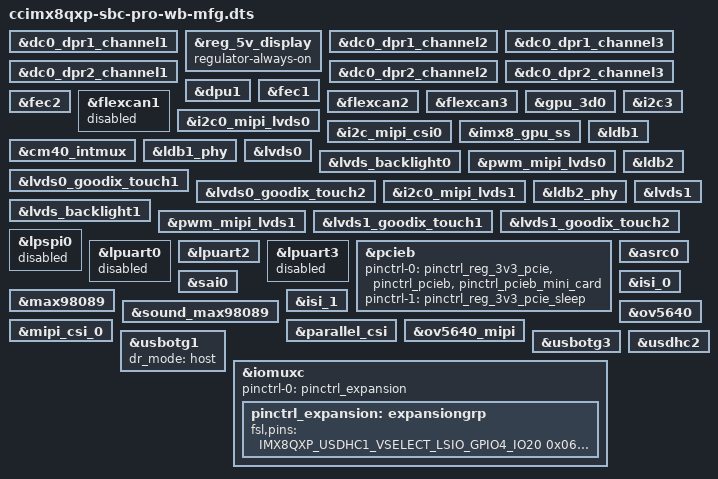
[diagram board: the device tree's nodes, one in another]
/*
 * Copyright 2018, Digi International Inc.
 *
 * Permission to use, copy, modify, and/or distribute this software for any
 * purpose with or without fee is hereby granted, provided that the above
 * copyright notice and this permission notice appear in all copies.
 * THE SOFTWARE IS PROVIDED "AS IS" AND THE AUTHOR DISCLAIMS ALL WARRANTIES
 * WITH REGARD TO THIS SOFTWARE INCLUDING ALL IMPLIED WARRANTIES OF
 * MERCHANTABILITY AND FITNESS. IN NO EVENT SHALL THE AUTHOR BE LIABLE FOR
 * ANY SPECIAL, DIRECT, INDIRECT, OR CONSEQUENTIAL DAMAGES OR ANY DAMAGES
 * WHATSOEVER RESULTING FROM LOSS OF USE, DATA OR PROFITS, WHETHER IN AN
 * ACTION OF CONTRACT, NEGLIGENCE OR OTHER TORTIOUS ACTION, ARISING OUT OF
 * OR IN CONNECTION WITH THE USE OR PERFORMANCE OF THIS SOFTWARE.
 */

/dts-v1/;

/* i.MX8QXP CPU */
#include "../freescale/imx8qxp.dtsi"
/* Digi ConnectCore 8X (WiFi/bluetooth variant) */
#include "ccimx8x-wb.dtsi"
/* Digi ConnectCore 8X SBC Pro */
#include "ccimx8x-sbc-pro.dtsi"

&dc0_dpr1_channel1 {
	status = "okay";
};

&reg_5v_display {
	regulator-always-on;
};

&dc0_dpr1_channel2 {
	status = "okay";
};

&dc0_dpr1_channel3 {
	status = "okay";
};

&dc0_dpr2_channel1 {
	status = "okay";
};

&dc0_dpr2_channel2 {
	status = "okay";
};

&dc0_dpr2_channel3 {
	status = "okay";
};

&dpu1 {
	status = "okay";
};

&fec1 {
	status = "okay";
};

&fec2 {
	status = "okay";
};

/*
 * CAN0
 * Conflicts with LPUART0 RTS/CTS lines.
 * Before enabling the port you need to configure
 * lpuart0 node as 2 wires.
 */
&flexcan1 {
	status = "disabled";
};

/* CAN1 on expansion header */
&flexcan2 {
	status = "okay";
};

/*
 * CAN2 on expansion header.
 * Conflicts with LPUART3 RX/TX lines.
 */
&flexcan3 {
	status = "okay";
};

&gpu_3d0 {
	status = "okay";
};

/*
 * I2C3 connected to Audio codec and USB 3.0 PD PHY.
 * Also available on:
 * - Expansion header
 * - PCIe connector
 * - Parallel Camera connector
 */
&i2c3 {
	status = "okay";
};

/* MIPI-DSI0 I2C available on LVDS0 connector */
&i2c0_mipi_lvds0 {
	status = "okay";
};

/* MIPI-CSI0 I2C available on MIPI Camera connector */
&i2c_mipi_csi0 {
	status = "okay";
};

&imx8_gpu_ss {
	status = "okay";
};

&cm40_intmux {
	status = "okay";
};

&ldb1 {
	status = "okay";
};

&ldb1_phy {
	status = "okay";
};

&lvds0 {
	status = "okay";
};

&lvds_backlight0 {
	status = "okay";
};

&pwm_mipi_lvds0 {
	status = "okay";
};

/*
 * On the CC8X SBC, an inconsistent reset sequence makes
 * the Goodix display's touch controller respond to two I2C
 * addresses: 0x14 and 0x5D. To make sure the touchscreen
 * works every time, the touch controller's description must
 * be duplicated for both addresses.
 */
&lvds0_goodix_touch1 {
	status = "okay";
};

&lvds0_goodix_touch2 {
	status = "okay";
};

/* MIPI-DSI1 I2C available on LVDS1 connector */
&i2c0_mipi_lvds1 {
	status = "okay";
};

&ldb2 {
	status = "okay";
};

&ldb2_phy {
	status = "okay";
};

&lvds1 {
	status = "okay";
};

&lvds_backlight1 {
	status = "okay";
};

&pwm_mipi_lvds1 {
	status = "okay";
};

&lvds1_goodix_touch1 {
	status = "okay";
};

&lvds1_goodix_touch2 {
	status = "okay";
};

/* LPSPI0 on expansion header */
&lpspi0 {
	status = "disabled";
};

/*
 * LPUART0 on expansion header.
 * RTS/CTS lines conflict with CAN0.
 */
&lpuart0 {
	status = "disabled";
};

/* Console */
&lpuart2 {
	status = "okay";
};

/*
 * LPUART3 on expansion header.
 * Conflicts with CAN2.
 */
&lpuart3 {
	status = "disabled";
};

/* PCIE (Wireless) and PCIe (Mini Card) */
&pcieb {
	pinctrl-names = "default", "sleep";
	pinctrl-0 = <&pinctrl_reg_3v3_pcie>, <&pinctrl_pcieb>, <&pinctrl_pcieb_mini_card>;
	pinctrl-1 = <&pinctrl_reg_3v3_pcie_sleep>;
};

/* Audio support */
&asrc0 {
	status = "okay";
};

&sai0 {
	status = "okay";
};

&max98089 {
	status = "okay";
};

&sound_max98089 {
	status = "okay";
};

&isi_0 {
	status = "okay";
};

&isi_1 {
	status = "okay";
};

/* Parallel camera */
&parallel_csi {
	status = "okay";
};

&ov5640 {
	status = "okay";
};

/* MIPI camera */
&mipi_csi_0 {
	status = "okay";
};

&ov5640_mipi {
	status = "okay";
};

/* USB_OTG1 */
&usbotg1 {
	/*
	 * To configure this USB controller as a device set dr_mode to "otg";
	 * to configure it as a host set to "host" instead.
	 */
	dr_mode = "host";
	status = "okay";
};

/* USB_OTG2/USB_SS3 */
&usbotg3 {
	status = "okay";
};

/* Micro SD card */
&usdhc2 {
	status = "okay";
};

/* IOMUX */
&iomuxc {
	pinctrl-names = "default";
	pinctrl-0 = <&pinctrl_expansion>;

	/* Expansion, MIPI and Parallel Camera Connectors */
	pinctrl_expansion: expansiongrp {
		fsl,pins = <
			/* Expansion connector */
			/* J20 connector */
			/* GPIO4_20 (J20 PIN13) */
			IMX8QXP_USDHC1_VSELECT_LSIO_GPIO4_IO20	0x06000020
			/* GPIO4_21 (J20 PIN14) */
			IMX8QXP_USDHC1_WP_LSIO_GPIO4_IO21		0x06000020

			/* J27 connector */
			/* SPI0_SCK (J27 PIN3) */
			IMX8QXP_SPI0_SCK_LSIO_GPIO1_IO04		0x06000020
			/* SPI0_CS0 (J27 PIN4) */
			IMX8QXP_SPI0_CS0_LSIO_GPIO1_IO08		0x06000020
			/* SPI0_SDI (J27 PIN5) */
			IMX8QXP_SPI0_SDI_LSIO_GPIO1_IO05		0x06000020
			/* SPI0_CS1 (J27 PIN6) */
			IMX8QXP_SPI0_CS1_LSIO_GPIO1_IO07		0x06000020
			/* SPI0_SDO (J27 PIN7) */
			IMX8QXP_SPI0_SDO_LSIO_GPIO1_IO06		0x06000020
			/* SPI0_IRQ_N (J27 PIN8) */
			IMX8QXP_SPI2_SDO_LSIO_GPIO1_IO01		0x06000020
			/* EXP_I2C_IRQ_N (J27 PIN14) */
			IMX8QXP_QSPI0A_SS1_B_LSIO_GPIO3_IO15	0x06000020
			/* EXP_I2C_GPIO (J27 PIN16) */
			IMX8QXP_QSPI0A_SS0_B_LSIO_GPIO3_IO14	0x06000020
			/* UART0_TX (J27 PIN17) */
			IMX8QXP_UART0_TX_LSIO_GPIO1_IO22		0x06000020
			/* UART0_RTS_B (J27 PIN18) */
			IMX8QXP_FLEXCAN0_RX_LSIO_GPIO1_IO15	0x06000020
			/* UART0_RX (J27 PIN19) */
			IMX8QXP_UART0_RX_LSIO_GPIO1_IO21		0x06000020
			/* UART0_CTS_B (J27 PIN20) */
			IMX8QXP_FLEXCAN0_TX_LSIO_GPIO1_IO16	0x06000020
			/* M40_UART_TX (J27 PIN21) */
			IMX8QXP_ADC_IN3_LSIO_GPIO1_IO11		0x06000020
			/* M40_UART_RX (J27 PIN23) */
			IMX8QXP_ADC_IN2_LSIO_GPIO1_IO12		0x06000020
			/* ADC_IN0 (J27 PIN25) */
			IMX8QXP_ADC_IN0_LSIO_GPIO1_IO10		0x06000020
			/* ADC_IN4 (J27 PIN26) */
			IMX8QXP_ADC_IN4_LSIO_GPIO1_IO14		0x06000020
			/* ADC_IN1 (J27 PIN27) */
			IMX8QXP_ADC_IN1_LSIO_GPIO1_IO09		0x06000020
			/* ADC_IN5 (J27 PIN28) */
			IMX8QXP_ADC_IN5_LSIO_GPIO1_IO13		0x06000020
			/* GPIO4_19 (J27 PIN30) */
			IMX8QXP_USDHC1_RESET_B_LSIO_GPIO4_IO19	0x06000020
			/* GPIO0_12 (J27 PIN36) */
			IMX8QXP_SPDIF0_EXT_CLK_LSIO_GPIO0_IO12	0x06000020
			/* GPIO5_09 (J27 PIN37) */
			IMX8QXP_ENET0_REFCLK_125M_25M_LSIO_GPIO5_IO09	0x06000020
		>;
	};
};
